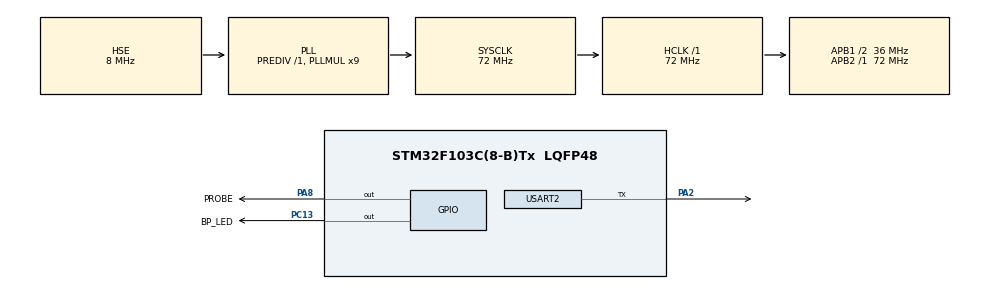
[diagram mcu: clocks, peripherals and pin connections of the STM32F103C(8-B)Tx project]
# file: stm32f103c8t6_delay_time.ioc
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Mcu.Family=STM32F1
Mcu.Name=STM32F103C(8-B)Tx
Mcu.Package=LQFP48
NVIC.PriorityGroup=NVIC_PRIORITYGROUP_4
PA13.Mode=Serial_Wire
PA13.Signal=SYS_JTMS-SWDIO
PA14.Mode=Serial_Wire
PA14.Signal=SYS_JTCK-SWCLK
PA2.Mode=Half_duplex(single_wire_mode)
PA2.Signal=USART2_TX
PA3.Signal=USART2_RX
PA8.GPIO_Label=PROBE
PA8.Signal=GPIO_Output
PC13-TAMPER-RTC.GPIO_Label=BP_LED
PC13-TAMPER-RTC.PinState=GPIO_PIN_SET
PC13-TAMPER-RTC.Signal=GPIO_Output
PD0-OSC_IN.Mode=HSE-External-Oscillator
PD0-OSC_IN.Signal=RCC_OSC_IN
PD1-OSC_OUT.Mode=HSE-External-Oscillator
PD1-OSC_OUT.Signal=RCC_OSC_OUT
ProjectManager.HeapSize=0x200
ProjectManager.StackSize=0x400
ProjectManager.TargetToolchain=STM32CubeIDE
RCC.AHBFreq_Value=72000000
RCC.APB1CLKDivider=RCC_HCLK_DIV2
RCC.APB1Freq_Value=36000000
RCC.APB1TimFreq_Value=72000000
RCC.APB2Freq_Value=72000000
RCC.APB2TimFreq_Value=72000000
RCC.HCLKFreq_Value=72000000
RCC.PLLMUL=RCC_PLL_MUL9
RCC.PLLSourceVirtual=RCC_PLLSOURCE_HSE
RCC.SYSCLKFreq_VALUE=72000000
RCC.SYSCLKSource=RCC_SYSCLKSOURCE_PLLCLK
RCC.USBFreq_Value=72000000
TIM1.AutoReloadPreload=TIM_AUTORELOAD_PRELOAD_DISABLE
TIM1.Period=90-1
TIM1.Prescaler=0
TIM1.RepetitionCounter=0
USART2.Mode=MODE_TX
USART2.VirtualMode=VM_ASYNC
VP_TIM1_VS_ClockSourceINT.Mode=Internal
board=custom

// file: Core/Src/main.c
/* USER CODE BEGIN Header */
/**
 ******************************************************************************
 * @file           : main.c
 * @brief          : Main program body
 ******************************************************************************
 * @attention
 *
 * Copyright (c) 2022 STMicroelectronics.
 * All rights reserved.
 *
 * This software is licensed under terms that can be found in the LICENSE file
 * in the root directory of this software component.
 * If no LICENSE file comes with this software, it is provided AS-IS.
 *
 ******************************************************************************
 */
/* USER CODE END Header */
#include "main.h"

TIM_HandleTypeDef htim1;

UART_HandleTypeDef huart2;

void SystemClock_Config(void);
static void MX_GPIO_Init(void);
static void MX_USART2_UART_Init(void);
static void MX_TIM1_Init(void);

/* USER CODE BEGIN 0 */

extern UART_HandleTypeDef huart2;

#ifdef __GNUC__
/* With GCC, small printf (option LD Linker->Libraries->Small printf
 set to 'Yes') calls __io_putchar() */
#define PUTCHAR_PROTOTYPE int __io_putchar(int ch)
#else
#define PUTCHAR_PROTOTYPE int fputc(int ch, FILE *f)
#endif /* __GNUC__ */

//must have this to print in uart com port
PUTCHAR_PROTOTYPE {
    // Place your implementation of fputc here
    // e.g. write a character to the EVAL_COM1 and Loop until the end of transmission
    HAL_UART_Transmit(&huart2, (uint8_t*) &ch, 1, 0xFFFF);

    return ch;
}

#define delay_100nanosec()  __NOP();__NOP();__NOP();__NOP();__NOP();__NOP();__NOP();
#define delay_200nanosec()   delay_100nanosec(); delay_100nanosec();
#define delay_300nanosec()   delay_100nanosec(); delay_200nanosec();
#define delay_400nanosec()   delay_200nanosec(); delay_200nanosec();
#define delay_500nanosec()   delay_200nanosec(); delay_300nanosec();
#define delay_1000nanosec()   delay_500nanosec(); delay_500nanosec();

// tested with bluepill @ 72MHz, with oscilloscope,  very accurate
// 1000us = 1ms
void delay_us(uint32_t time) {
    uint32_t i = 8 * time;
    while (i--)
        ;
}

void test_delay_us() {
    while (1) {
        HAL_GPIO_WritePin(PROBE_GPIO_Port, PROBE_Pin, GPIO_PIN_SET);
        delay_us(1000);
        HAL_GPIO_WritePin(PROBE_GPIO_Port, PROBE_Pin, GPIO_PIN_RESET);
        delay_us(500);

    }

}

void MY_HAL_GPIO_WritePin(GPIO_TypeDef *GPIOx, uint16_t GPIO_Pin, GPIO_PinState PinState) {
    /* Check the parameters */

    if (PinState != GPIO_PIN_RESET) {
        GPIOx->BSRR = GPIO_Pin;
    } else {
        GPIOx->BSRR = (uint32_t) GPIO_Pin << 16u;
    }
}

void test_delay_100nanosec() {
    while (1) {
        // without any nop or delay,  high 650ns, low 650ns
        //HAL_GPIO_WritePin(PROBE_GPIO_Port, PROBE_Pin, GPIO_PIN_SET);

        GPIOA->BSRR  = (1 << 8); // Set the Pin PA8
        // no __NOP(): use 250ns
        // 5 __NOP(): use 300ns
        //  __NOP();
        // asm("NOP");
        //delay_100nanos(1); // delay 100ns X 10=1000us
        __NOP();
        __NOP();
        __NOP();
        __NOP();
        __NOP();
        GPIOA->BSRR  = (1 << 24);  // Set the Pin PA8 RESET
        //delay_100nanos(1); // delay 100ns X 10=1000us
        //__NOP(); // 700ns per nop
        //HAL_GPIO_WritePin(PROBE_GPIO_Port, PROBE_Pin, GPIO_PIN_RESET);
        //__NOP();// 700ns per nop
        //delay_100nanos(10); // delay 100ns X 10=1000us

    }

}

void test_delay_500nanos() {
    while (1) {
        GPIOA->BSRR = PROBE_Pin; // Set the Pin PA8
        GPIOA->BSRR  = (uint32_t) PROBE_Pin << 16u;;  // Set the Pin PA8 RESET

        GPIOA->BSRR = PROBE_Pin; // Set the Pin PA8

        delay_500nanosec( );
        GPIOA->BSRR  = (uint32_t) PROBE_Pin << 16u;;  // Set the Pin PA8 RESET

    }

}

void test_HAL_gpio_speed() {
    while (1) {
        HAL_GPIO_WritePin(GPIOA, GPIO_PIN_7, GPIO_PIN_SET);

        MY_HAL_GPIO_WritePin(PROBE_GPIO_Port, PROBE_Pin, GPIO_PIN_SET);
        // 800 nanos

        MY_HAL_GPIO_WritePin(PROBE_GPIO_Port, PROBE_Pin, GPIO_PIN_RESET);
        // 800 nanos

    }
}

// 72MHz
void test_LL_gpio_speed() {
    while (1) {

        GPIOA->BSRR = PROBE_Pin; // Set the Pin PA8 overwrite PA7
        // 150nanos

         GPIOA->BSRR = (uint32_t) PROBE_Pin << 16u;

        // 150nanos

    }
}

/* USER CODE END 0 */

int main(void)
{

  /* MCU Configuration--------------------------------------------------------*/

  /* Reset of all peripherals, Initializes the Flash interface and the Systick. */
  HAL_Init();

  /* Configure the system clock */
  SystemClock_Config();

  /* Initialize all configured peripherals */
  MX_GPIO_Init();
  MX_USART2_UART_Init();
  MX_TIM1_Init();

  /* Infinite loop */
  /* USER CODE BEGIN WHILE */
    HAL_GPIO_WritePin(GPIOA, GPIO_PIN_7, GPIO_PIN_SET);

    while (1) {
        HAL_Delay(10);
        //test_HAL_gpio_speed();
        test_delay_500nanos();
        //test_delay_us();
        //test_delay_500nanos();
    /* USER CODE END WHILE */

    }
}

void SystemClock_Config(void)
{
  RCC_OscInitTypeDef RCC_OscInitStruct = {0};
  RCC_ClkInitTypeDef RCC_ClkInitStruct = {0};

  /** Initializes the RCC Oscillators according to the specified parameters
  * in the RCC_OscInitTypeDef structure.
  */
  RCC_OscInitStruct.OscillatorType = RCC_OSCILLATORTYPE_HSE;
  RCC_OscInitStruct.HSEState = RCC_HSE_ON;
  RCC_OscInitStruct.HSEPredivValue = RCC_HSE_PREDIV_DIV1;
  RCC_OscInitStruct.HSIState = RCC_HSI_ON;
  RCC_OscInitStruct.PLL.PLLState = RCC_PLL_ON;
  RCC_OscInitStruct.PLL.PLLSource = RCC_PLLSOURCE_HSE;
  RCC_OscInitStruct.PLL.PLLMUL = RCC_PLL_MUL9;
  if (HAL_RCC_OscConfig(&RCC_OscInitStruct) != HAL_OK)
  {
    Error_Handler();
  }

  /** Initializes the CPU, AHB and APB buses clocks
  */
  RCC_ClkInitStruct.ClockType = RCC_CLOCKTYPE_HCLK|RCC_CLOCKTYPE_SYSCLK
                              |RCC_CLOCKTYPE_PCLK1|RCC_CLOCKTYPE_PCLK2;
  RCC_ClkInitStruct.SYSCLKSource = RCC_SYSCLKSOURCE_PLLCLK;
  RCC_ClkInitStruct.AHBCLKDivider = RCC_SYSCLK_DIV1;
  RCC_ClkInitStruct.APB1CLKDivider = RCC_HCLK_DIV2;
  RCC_ClkInitStruct.APB2CLKDivider = RCC_HCLK_DIV1;

  if (HAL_RCC_ClockConfig(&RCC_ClkInitStruct, FLASH_LATENCY_2) != HAL_OK)
  {
    Error_Handler();
  }
}

static void MX_TIM1_Init(void)
{

  TIM_ClockConfigTypeDef sClockSourceConfig = {0};
  TIM_MasterConfigTypeDef sMasterConfig = {0};

  htim1.Instance = TIM1;
  htim1.Init.Prescaler = 0;
  htim1.Init.CounterMode = TIM_COUNTERMODE_UP;
  htim1.Init.Period = 90-1;
  htim1.Init.ClockDivision = TIM_CLOCKDIVISION_DIV1;
  htim1.Init.RepetitionCounter = 0;
  htim1.Init.AutoReloadPreload = TIM_AUTORELOAD_PRELOAD_DISABLE;
  if (HAL_TIM_Base_Init(&htim1) != HAL_OK)
  {
    Error_Handler();
  }
  sClockSourceConfig.ClockSource = TIM_CLOCKSOURCE_INTERNAL;
  if (HAL_TIM_ConfigClockSource(&htim1, &sClockSourceConfig) != HAL_OK)
  {
    Error_Handler();
  }
  sMasterConfig.MasterOutputTrigger = TIM_TRGO_RESET;
  sMasterConfig.MasterSlaveMode = TIM_MASTERSLAVEMODE_DISABLE;
  if (HAL_TIMEx_MasterConfigSynchronization(&htim1, &sMasterConfig) != HAL_OK)
  {
    Error_Handler();
  }

}

static void MX_USART2_UART_Init(void)
{

  huart2.Instance = USART2;
  huart2.Init.BaudRate = 115200;
  huart2.Init.WordLength = UART_WORDLENGTH_8B;
  huart2.Init.StopBits = UART_STOPBITS_1;
  huart2.Init.Parity = UART_PARITY_NONE;
  huart2.Init.Mode = UART_MODE_TX;
  huart2.Init.HwFlowCtl = UART_HWCONTROL_NONE;
  huart2.Init.OverSampling = UART_OVERSAMPLING_16;
  if (HAL_HalfDuplex_Init(&huart2) != HAL_OK)
  {
    Error_Handler();
  }

}

static void MX_GPIO_Init(void)
{
  GPIO_InitTypeDef GPIO_InitStruct = {0};

  /* GPIO Ports Clock Enable */
  __HAL_RCC_GPIOC_CLK_ENABLE();
  __HAL_RCC_GPIOD_CLK_ENABLE();
  __HAL_RCC_GPIOA_CLK_ENABLE();

  /*Configure GPIO pin Output Level */
  HAL_GPIO_WritePin(BP_LED_GPIO_Port, BP_LED_Pin, GPIO_PIN_SET);

  /*Configure GPIO pin Output Level */
  HAL_GPIO_WritePin(PROBE_GPIO_Port, PROBE_Pin, GPIO_PIN_RESET);

  /*Configure GPIO pin : BP_LED_Pin */
  GPIO_InitStruct.Pin = BP_LED_Pin;
  GPIO_InitStruct.Mode = GPIO_MODE_OUTPUT_PP;
  GPIO_InitStruct.Pull = GPIO_NOPULL;
  GPIO_InitStruct.Speed = GPIO_SPEED_FREQ_LOW;
  HAL_GPIO_Init(BP_LED_GPIO_Port, &GPIO_InitStruct);

  /*Configure GPIO pin : PROBE_Pin */
  GPIO_InitStruct.Pin = PROBE_Pin;
  GPIO_InitStruct.Mode = GPIO_MODE_OUTPUT_PP;
  GPIO_InitStruct.Pull = GPIO_NOPULL;
  GPIO_InitStruct.Speed = GPIO_SPEED_FREQ_LOW;
  HAL_GPIO_Init(PROBE_GPIO_Port, &GPIO_InitStruct);

}

void Error_Handler(void)
{
    __disable_irq();
    while (1) {
    }
}
